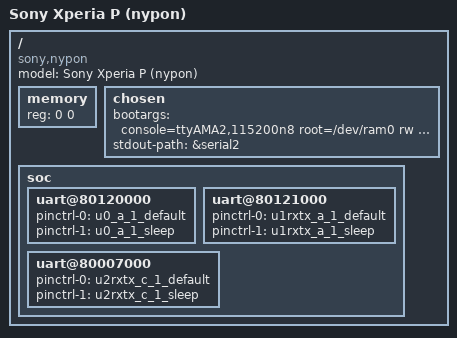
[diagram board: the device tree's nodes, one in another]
// SPDX-License-Identifier: GPL-2.0-only
/dts-v1/;

/ {
	model = "Sony Xperia P (nypon)";
	compatible = "sony,nypon", "st-ericsson,u8500";

	memory {
		device_type = "memory";
		reg = <0 0>;
	};

	chosen {
		bootargs = "console=ttyAMA2,115200n8 root=/dev/ram0 rw rootwait";
		stdout-path = &serial2;
	};

	soc {

		uart@80120000 {
			pinctrl-names = "default", "sleep";
			pinctrl-0 = <&u0_a_1_default>;
			pinctrl-1 = <&u0_a_1_sleep>;
			status = "okay";
		};

		/* This UART is unused and thus left disabled */
		uart@80121000 {
			pinctrl-names = "default", "sleep";
			pinctrl-0 = <&u1rxtx_a_1_default>;
			pinctrl-1 = <&u1rxtx_a_1_sleep>;
			status = "okay";
		};

		uart@80007000 {
			pinctrl-names = "default", "sleep";
			pinctrl-0 = <&u2rxtx_c_1_default>;
			pinctrl-1 = <&u2rxtx_c_1_sleep>;
			status = "okay";
		};
	};

};
